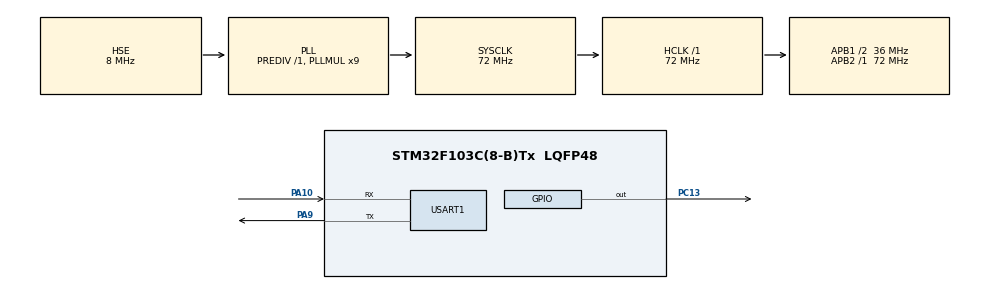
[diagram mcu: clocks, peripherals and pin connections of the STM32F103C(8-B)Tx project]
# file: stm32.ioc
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Dma.Request0=USART1_RX
Dma.Request1=USART1_TX
Dma.USART1_RX.0.Direction=DMA_PERIPH_TO_MEMORY
Dma.USART1_RX.0.Instance=DMA1_Channel5
Dma.USART1_RX.0.MemDataAlignment=DMA_MDATAALIGN_BYTE
Dma.USART1_RX.0.MemInc=DMA_MINC_ENABLE
Dma.USART1_RX.0.Mode=DMA_NORMAL
Dma.USART1_RX.0.PeriphDataAlignment=DMA_PDATAALIGN_BYTE
Dma.USART1_RX.0.PeriphInc=DMA_PINC_DISABLE
Dma.USART1_RX.0.Priority=DMA_PRIORITY_LOW
Dma.USART1_TX.1.Direction=DMA_MEMORY_TO_PERIPH
Dma.USART1_TX.1.Instance=DMA1_Channel4
Dma.USART1_TX.1.MemDataAlignment=DMA_MDATAALIGN_BYTE
Dma.USART1_TX.1.MemInc=DMA_MINC_ENABLE
Dma.USART1_TX.1.Mode=DMA_NORMAL
Dma.USART1_TX.1.PeriphDataAlignment=DMA_PDATAALIGN_BYTE
Dma.USART1_TX.1.PeriphInc=DMA_PINC_DISABLE
Dma.USART1_TX.1.Priority=DMA_PRIORITY_LOW
Mcu.Family=STM32F1
Mcu.Name=STM32F103C(8-B)Tx
Mcu.Package=LQFP48
NVIC.DMA1_Channel4_IRQn=true\:0\:0\:false\:false\:true\:false\:true\:true
NVIC.DMA1_Channel5_IRQn=true\:0\:0\:false\:false\:true\:false\:true\:true
NVIC.PriorityGroup=NVIC_PRIORITYGROUP_4
NVIC.USART1_IRQn=true\:0\:0\:false\:false\:true\:true\:true\:true
PA10.Mode=Asynchronous
PA10.Signal=USART1_RX
PA13.Mode=Serial_Wire
PA13.Signal=SYS_JTMS-SWDIO
PA14.Mode=Serial_Wire
PA14.Signal=SYS_JTCK-SWCLK
PA9.Mode=Asynchronous
PA9.Signal=USART1_TX
PC13-TAMPER-RTC.GPIO_Speed=GPIO_SPEED_FREQ_HIGH
PC13-TAMPER-RTC.Signal=GPIO_Output
PD0-OSC_IN.Mode=HSE-External-Oscillator
PD0-OSC_IN.Signal=RCC_OSC_IN
PD1-OSC_OUT.Mode=HSE-External-Oscillator
PD1-OSC_OUT.Signal=RCC_OSC_OUT
ProjectManager.HeapSize=0x200
ProjectManager.StackSize=0x400
ProjectManager.TargetToolchain=MDK-ARM V5.32
RCC.AHBFreq_Value=72000000
RCC.APB1CLKDivider=RCC_HCLK_DIV2
RCC.APB1Freq_Value=36000000
RCC.APB1TimFreq_Value=72000000
RCC.APB2Freq_Value=72000000
RCC.APB2TimFreq_Value=72000000
RCC.HCLKFreq_Value=72000000
RCC.PLLMUL=RCC_PLL_MUL9
RCC.PLLSourceVirtual=RCC_PLLSOURCE_HSE
RCC.SYSCLKFreq_VALUE=72000000
RCC.SYSCLKSource=RCC_SYSCLKSOURCE_PLLCLK
RCC.USBFreq_Value=72000000
TIM1.Period=0xffff-1
TIM1.Prescaler=71
USART1.VirtualMode=VM_ASYNC
VP_TIM1_VS_ClockSourceINT.Mode=Internal
board=custom

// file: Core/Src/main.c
/* USER CODE BEGIN Header */
/**
  ******************************************************************************
  * @file           : main.c
  * @brief          : Main program body
  ******************************************************************************
  * @attention
  *
  * Copyright (c) 2023 STMicroelectronics.
  * All rights reserved.
  *
  * This software is licensed under terms that can be found in the LICENSE file
  * in the root directory of this software component.
  * If no LICENSE file comes with this software, it is provided AS-IS.
  *
  ******************************************************************************
  */
/* USER CODE END Header */
#include "main.h"

/* USER CODE BEGIN Includes */
#include "stdio.h"
#include "DHT.h"
#include "delay_timer.h"
#include "App.h"

 /**USART1 GPIO Configuration
    PA9     ------> USART1_TX
    PA10     ------> USART1_RX
    */
/* USER CODE END Includes */

/* USER CODE BEGIN PTD */

/** Size of buffer for transmit and receive UART*/
#define RX_SIZE 50
#define TX_SIZE 50

/* USER CODE END PTD */

TIM_HandleTypeDef htim1;

UART_HandleTypeDef huart1;
DMA_HandleTypeDef hdma_usart1_rx;
DMA_HandleTypeDef hdma_usart1_tx;

/* USER CODE BEGIN PV */

/** Sensor declaration */
DHT_Name DHTfromSTM32;
App_Init_t App;

/** Sensor detect start frame for transmit UART*/
typedef enum
{
	DHT_Sensor = 0u,
}Sensor_Dec_t;

/** Flag when allowing to read sensor*/
uint8_t DHTReadFlag = 0;

/** Flag when allowing to read sensor*/
uint8_t DHTTransFlag = 0;

Actuator_Init_t Actuators[MAX_ACTUATOR];

/** Flag when trasmit or recieve UART*/
uint8_t DataTransmitFlag = 0;
uint8_t DataReceiveFlag = 0;

/* Declare Buffer for transmit and receive UART

*/
char rxBuffer[RX_SIZE] = {0};
char txBuffer[TX_SIZE] = {0};
char buffer[10] = {0};

uint8_t msg[11] = "Hello esp32";
uint8_t size = 0;
int cur_time = 0;
/* USER CODE END PV */

void SystemClock_Config(void);
static void MX_GPIO_Init(void);
static void MX_DMA_Init(void);
static void MX_USART1_UART_Init(void);
static void MX_TIM1_Init(void);
/* USER CODE BEGIN PFP */
/*
void HAL_UARTEx_RxEventCallback(UART_HandleTypeDef *huart, uint16_t Size)
{
	HAL_UARTEx_ReceiveToIdle_DMA(&huart1,rxBuffer, RX_SIZE);
	size = Size;

}
*/
/* Hàm g?i l?i x? lý ph?c v? ng?t UART */
void HAL_UARTEx_RxEventCallback(UART_HandleTypeDef *huart, uint16_t Size)
{

      checkCommand(&App);
      DataReceiveFlag = 1;

      //HAL_UART_Transmit(huart, (uint8_t *) "\n", 1, 100);
      //HAL_UART_Transmit(huart, (uint8_t *) rxBuffer, strlen(rxBuffer), 100);
     	HAL_UARTEx_ReceiveToIdle_DMA(&huart1, (uint8_t*)App.rxBuffer, RX_SIZE);
		__HAL_DMA_DISABLE_IT(&hdma_usart1_rx,DMA_IT_HT);
}
void HAL_UART_TxCpltCallback(UART_HandleTypeDef *huart)
{
	/*HAL_UART_Transmit_DMA(&huart1,msg,11);*/
	/*HAL_UART_Transmit_IT(&huart1, msg, sizeof (msg));*/
}

/* USER CODE END PFP */

/* USER CODE BEGIN 0 */

HAL_StatusTypeDef readDataFromDHT(DHT_Name *DHT, uint8_t *str_buf );

/* USER CODE END 0 */

int main(void)
{

  /* MCU Configuration--------------------------------------------------------*/

  /* Reset of all peripherals, Initializes the Flash interface and the Systick. */
  HAL_Init();

  /* Configure the system clock */
  SystemClock_Config();

  /* Initialize all configured peripherals */
  MX_GPIO_Init();
  MX_DMA_Init();
  MX_USART1_UART_Init();
  MX_TIM1_Init();
  /* USER CODE BEGIN 2 */
  /**DHT initialization */
  DHT_Init(&DHTfromSTM32,DHT11,&htim1,GPIOB,GPIO_PIN_15);

  ActuatorInit(Actuators,Actuator_Off,GPIOA,GPIO_PIN_0);
  ActuatorInit(Actuators,Actuator_Off,GPIOA,GPIO_PIN_1);
  ActuatorInit(Actuators,Actuator_Off,GPIOA,GPIO_PIN_2);

  appInit(&App,&Actuators[0],&huart1,rxBuffer,txBuffer,RX_SIZE,TX_SIZE);

  /**Actuator init begin*/
  /*

  */
  /*Actuator init end*/
  HAL_UART_Transmit_DMA(&huart1, msg, sizeof (msg));
	HAL_UARTEx_ReceiveToIdle_DMA(&huart1, (uint8_t*)App.rxBuffer, RX_SIZE);
  /*
	HAL_UARTEx_ReceiveToIdle_DMA(&huart1, rxBuffer, RX_SIZE);

	*/
	__HAL_DMA_DISABLE_IT(&hdma_usart1_rx,DMA_IT_HT);
  /* USER CODE END 2 */

  /* Infinite loop */
  while (1)
  {

    /* USER CODE BEGIN 3 */
	  if(DataReceiveFlag == 1)
	  {
		  commandHandler(&App);
		  DataReceiveFlag = 0;
	  }
	  // HAL_Delay(1000);

  }
  /* USER CODE END 3 */
}

void SystemClock_Config(void)
{
  RCC_OscInitTypeDef RCC_OscInitStruct = {0};
  RCC_ClkInitTypeDef RCC_ClkInitStruct = {0};

  /** Initializes the RCC Oscillators according to the specified parameters
  * in the RCC_OscInitTypeDef structure.
  */
  RCC_OscInitStruct.OscillatorType = RCC_OSCILLATORTYPE_HSE;
  RCC_OscInitStruct.HSEState = RCC_HSE_ON;
  RCC_OscInitStruct.HSEPredivValue = RCC_HSE_PREDIV_DIV1;
  RCC_OscInitStruct.HSIState = RCC_HSI_ON;
  RCC_OscInitStruct.PLL.PLLState = RCC_PLL_ON;
  RCC_OscInitStruct.PLL.PLLSource = RCC_PLLSOURCE_HSE;
  RCC_OscInitStruct.PLL.PLLMUL = RCC_PLL_MUL9;
  if (HAL_RCC_OscConfig(&RCC_OscInitStruct) != HAL_OK)
  {
    Error_Handler();
  }

  /** Initializes the CPU, AHB and APB buses clocks
  */
  RCC_ClkInitStruct.ClockType = RCC_CLOCKTYPE_HCLK|RCC_CLOCKTYPE_SYSCLK
                              |RCC_CLOCKTYPE_PCLK1|RCC_CLOCKTYPE_PCLK2;
  RCC_ClkInitStruct.SYSCLKSource = RCC_SYSCLKSOURCE_PLLCLK;
  RCC_ClkInitStruct.AHBCLKDivider = RCC_SYSCLK_DIV1;
  RCC_ClkInitStruct.APB1CLKDivider = RCC_HCLK_DIV2;
  RCC_ClkInitStruct.APB2CLKDivider = RCC_HCLK_DIV1;

  if (HAL_RCC_ClockConfig(&RCC_ClkInitStruct, FLASH_LATENCY_2) != HAL_OK)
  {
    Error_Handler();
  }
}

static void MX_TIM1_Init(void)
{

  TIM_ClockConfigTypeDef sClockSourceConfig = {0};
  TIM_MasterConfigTypeDef sMasterConfig = {0};

  htim1.Instance = TIM1;
  htim1.Init.Prescaler = 71;
  htim1.Init.CounterMode = TIM_COUNTERMODE_UP;
  htim1.Init.Period = 0xffff-1;
  htim1.Init.ClockDivision = TIM_CLOCKDIVISION_DIV1;
  htim1.Init.RepetitionCounter = 0;
  htim1.Init.AutoReloadPreload = TIM_AUTORELOAD_PRELOAD_DISABLE;
  if (HAL_TIM_Base_Init(&htim1) != HAL_OK)
  {
    Error_Handler();
  }
  sClockSourceConfig.ClockSource = TIM_CLOCKSOURCE_INTERNAL;
  if (HAL_TIM_ConfigClockSource(&htim1, &sClockSourceConfig) != HAL_OK)
  {
    Error_Handler();
  }
  sMasterConfig.MasterOutputTrigger = TIM_TRGO_RESET;
  sMasterConfig.MasterSlaveMode = TIM_MASTERSLAVEMODE_DISABLE;
  if (HAL_TIMEx_MasterConfigSynchronization(&htim1, &sMasterConfig) != HAL_OK)
  {
    Error_Handler();
  }

}

static void MX_USART1_UART_Init(void)
{

  huart1.Instance = USART1;
  huart1.Init.BaudRate = 115200;
  huart1.Init.WordLength = UART_WORDLENGTH_8B;
  huart1.Init.StopBits = UART_STOPBITS_1;
  huart1.Init.Parity = UART_PARITY_NONE;
  huart1.Init.Mode = UART_MODE_TX_RX;
  huart1.Init.HwFlowCtl = UART_HWCONTROL_NONE;
  huart1.Init.OverSampling = UART_OVERSAMPLING_16;
  if (HAL_UART_Init(&huart1) != HAL_OK)
  {
    Error_Handler();
  }

}

static void MX_DMA_Init(void)
{

  /* DMA controller clock enable */
  __HAL_RCC_DMA1_CLK_ENABLE();

  /* DMA interrupt init */
  /* DMA1_Channel4_IRQn interrupt configuration */
  HAL_NVIC_SetPriority(DMA1_Channel4_IRQn, 0, 0);
  HAL_NVIC_EnableIRQ(DMA1_Channel4_IRQn);
  /* DMA1_Channel5_IRQn interrupt configuration */
  HAL_NVIC_SetPriority(DMA1_Channel5_IRQn, 0, 0);
  HAL_NVIC_EnableIRQ(DMA1_Channel5_IRQn);

}

static void MX_GPIO_Init(void)
{
  GPIO_InitTypeDef GPIO_InitStruct = {0};

  /* GPIO Ports Clock Enable */
  __HAL_RCC_GPIOC_CLK_ENABLE();
  __HAL_RCC_GPIOD_CLK_ENABLE();
  __HAL_RCC_GPIOA_CLK_ENABLE();

  /*Configure GPIO pin Output Level */
  HAL_GPIO_WritePin(GPIOC, GPIO_PIN_13, GPIO_PIN_RESET);

  /*Configure GPIO pin : PC13 */
  GPIO_InitStruct.Pin = GPIO_PIN_13;
  GPIO_InitStruct.Mode = GPIO_MODE_OUTPUT_PP;
  GPIO_InitStruct.Pull = GPIO_NOPULL;
  GPIO_InitStruct.Speed = GPIO_SPEED_FREQ_HIGH;
  HAL_GPIO_Init(GPIOC, &GPIO_InitStruct);

/* USER CODE BEGIN MX_GPIO_Init_2 */
  /*Configure GPIO pin : PB18 */
  GPIO_InitStruct.Pin = GPIO_PIN_15;
  GPIO_InitStruct.Mode = GPIO_MODE_INPUT;
  GPIO_InitStruct.Pull = GPIO_PULLUP;
  GPIO_InitStruct.Speed = GPIO_SPEED_FREQ_HIGH;
  HAL_GPIO_Init(GPIOB, &GPIO_InitStruct);
/* USER CODE END MX_GPIO_Init_2 */
}

/* USER CODE BEGIN 4 */

/*TODO : Check if this pin has been used*/

HAL_StatusTypeDef readDataFromDHT(DHT_Name *DHT, uint8_t *str_buf )
{
	if(DHT_ReadTempHum(DHT) == DHT_OK)
	{
		sprintf((char*)str_buf,"%d%d%d%d",DHT->Humi1,DHT->Humi2,DHT->Temp1,DHT->Temp2);
		DHTTransFlag = 1;
		return HAL_OK;
	}
	return HAL_ERROR;
}
/* USER CODE END 4 */

void Error_Handler(void)
{
  __disable_irq();
  while (1)
  {
  }
}
